# CY8C5888LTI_LP097 register map
File version: 0.1
CY8C58LP
Registers are 8-bit, read-write, no defined reset value unless marked. A register's access mark holds for its fields unless they carry their own. Offsets are from the block's base; lines under a group give offsets from that group; [hi:lo] are bit positions; {n}, {i} and the like mark numbered series; 'fields as' and 'values as' point back to an identical list; <NAME> marks a mode.

## Memory map
0x00000000 LEDs_9_10
0x00000000 USB — USBFS
0x00000000 LEDs_1_8
0x00000000 Status_9_11
0x00000000 Status_1_8

## LEDs_9_10
Base 0x00000000
0x40006577 LEDs_9_10_CONTROL_REG

## LEDs_1_8
Base 0x00000000
0x40006576 LEDs_1_8_CONTROL_REG

## Status_9_11
Base 0x00000000
0x40006567 Status_9_11_STATUS_REG
0x40006587 Status_9_11_MASK_REG
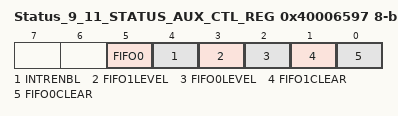
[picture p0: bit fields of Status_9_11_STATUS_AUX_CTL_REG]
0x40006597 Status_9_11_STATUS_AUX_CTL_REG
  [5] FIFO0 — FIFO0 clear
    1=ENABLED (Enable counter); 0=DISABLED (Disable counter)
  [4] INTRENBL — Enables or disables the Interrupt
    1=ENABLED (Interrupt enabled); 0=DISABLED (Interrupt disabled)
  [3] FIFO1LEVEL — FIFO level
    1=ENABLED (FIFO LVL: input mode: FIFO at least 1/2 empty; output mode: FIFO at least 1/2 full); 0=DISABLED (FIFO LVL: input mode: FIFO not full; output mode: FIFO not empty)
  [2] FIFO0LEVEL — FIFO level
    values as FIFO1LEVEL
  [1] FIFO1CLEAR — FIFO clear
    1=ENABLED (Clear FIFO state); 0=DISABLED (Normal FIFO operation)
  [0] FIFO0CLEAR — FIFO clear
    values as FIFO1CLEAR

## Status_1_8
Base 0x00000000
0x40006566 Status_1_8_STATUS_REG
0x40006586 Status_1_8_MASK_REG
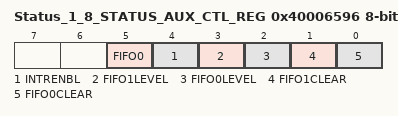
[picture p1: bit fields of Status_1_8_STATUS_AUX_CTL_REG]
0x40006596 Status_1_8_STATUS_AUX_CTL_REG
  [5] FIFO0 — FIFO0 clear
    1=ENABLED (Enable counter); 0=DISABLED (Disable counter)
  [4] INTRENBL — Enables or disables the Interrupt
    1=ENABLED (Interrupt enabled); 0=DISABLED (Interrupt disabled)
  [3] FIFO1LEVEL — FIFO level
    1=ENABLED (FIFO LVL: input mode: FIFO at least 1/2 empty; output mode: FIFO at least 1/2 full); 0=DISABLED (FIFO LVL: input mode: FIFO not full; output mode: FIFO not empty)
  [2] FIFO0LEVEL — FIFO level
    values as FIFO1LEVEL
  [1] FIFO1CLEAR — FIFO clear
    1=ENABLED (Clear FIFO state); 0=DISABLED (Normal FIFO operation)
  [0] FIFO0CLEAR — FIFO clear
    values as FIFO1CLEAR
